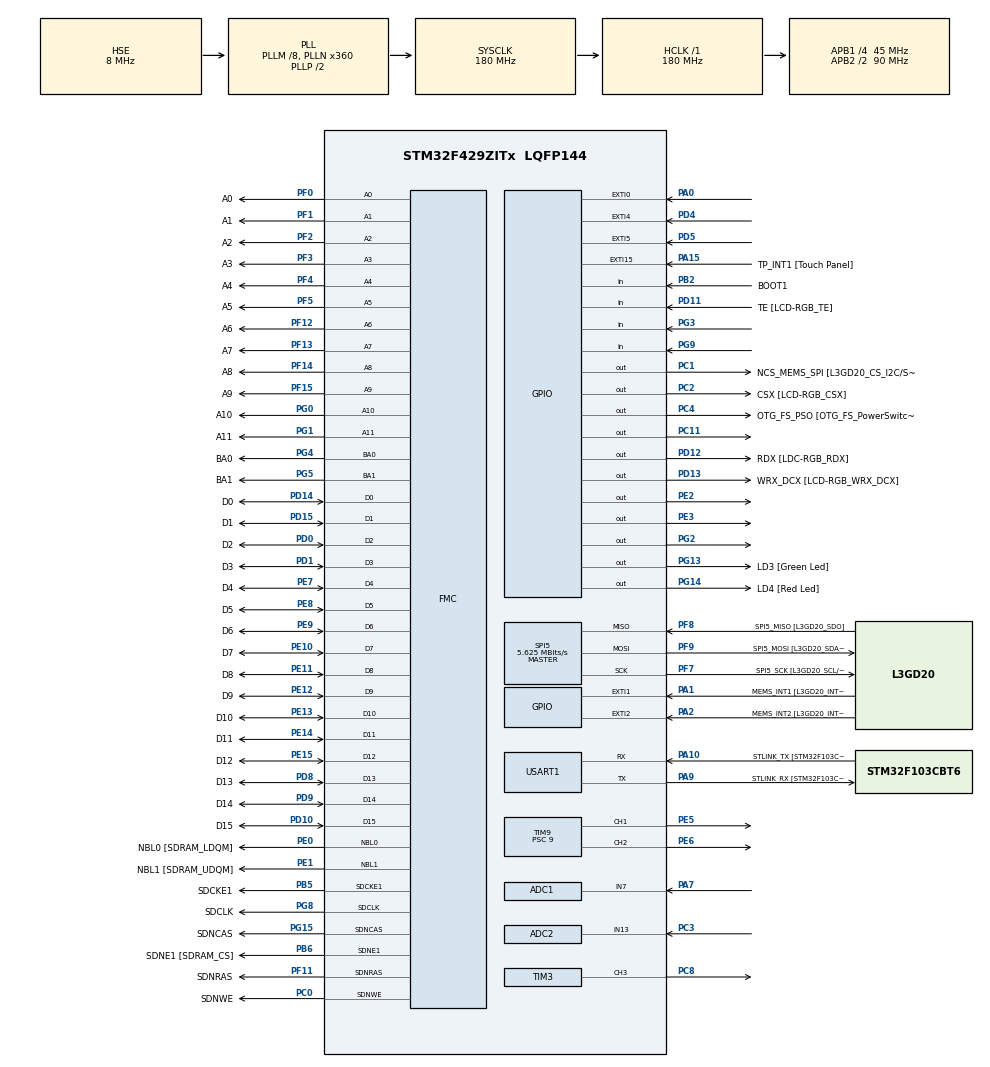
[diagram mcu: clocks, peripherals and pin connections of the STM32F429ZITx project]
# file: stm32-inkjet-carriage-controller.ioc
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ADC1.Channel-0\#ChannelRegularConversion=ADC_CHANNEL_7
ADC1.Mode=__NULL
ADC1.NbrOfConversionFlag=1
ADC1.Rank-0\#ChannelRegularConversion=1
ADC1.SamplingTime-0\#ChannelRegularConversion=ADC_SAMPLETIME_15CYCLES
ADC1.master=1
ADC2.Channel-0\#ChannelRegularConversion=ADC_CHANNEL_13
ADC2.NbrOfConversionFlag=1
ADC2.Rank-0\#ChannelRegularConversion=1
ADC2.SamplingTime-0\#ChannelRegularConversion=ADC_SAMPLETIME_15CYCLES
Dma.ADC1.0.Direction=DMA_PERIPH_TO_MEMORY
Dma.ADC1.0.FIFOMode=DMA_FIFOMODE_DISABLE
Dma.ADC1.0.Instance=DMA2_Stream0
Dma.ADC1.0.MemDataAlignment=DMA_MDATAALIGN_HALFWORD
Dma.ADC1.0.MemInc=DMA_MINC_ENABLE
Dma.ADC1.0.Mode=DMA_NORMAL
Dma.ADC1.0.PeriphDataAlignment=DMA_PDATAALIGN_HALFWORD
Dma.ADC1.0.PeriphInc=DMA_PINC_DISABLE
Dma.ADC1.0.Priority=DMA_PRIORITY_HIGH
Dma.ADC2.1.Direction=DMA_PERIPH_TO_MEMORY
Dma.ADC2.1.FIFOMode=DMA_FIFOMODE_DISABLE
Dma.ADC2.1.Instance=DMA2_Stream2
Dma.ADC2.1.MemDataAlignment=DMA_MDATAALIGN_HALFWORD
Dma.ADC2.1.MemInc=DMA_MINC_ENABLE
Dma.ADC2.1.Mode=DMA_NORMAL
Dma.ADC2.1.PeriphDataAlignment=DMA_PDATAALIGN_HALFWORD
Dma.ADC2.1.PeriphInc=DMA_PINC_DISABLE
Dma.ADC2.1.Priority=DMA_PRIORITY_HIGH
Dma.Request0=ADC1
Dma.Request1=ADC2
FMC.CASLatency1=FMC_SDRAM_CAS_LATENCY_3
FMC.ExitSelfRefreshDelay1=7
FMC.LoadToActiveDelay1=2
FMC.RCDDelay1=2
FMC.RPDelay1=2
FMC.RPDelay2=2
FMC.ReadBurst1=FMC_SDRAM_RBURST_DISABLE
FMC.ReadPipeDelay1=FMC_SDRAM_RPIPE_DELAY_1
FMC.ReadPipeDelay2=FMC_SDRAM_RPIPE_DELAY_1
FMC.RowCycleDelay1=7
FMC.RowCycleDelay2=7
FMC.SDClockPeriod1=FMC_SDRAM_CLOCK_PERIOD_2
FMC.SDClockPeriod2=FMC_SDRAM_CLOCK_PERIOD_2
FMC.SelfRefreshTime1=4
FMC.WriteRecoveryTime1=3
Mcu.Family=STM32F4
Mcu.Name=STM32F429ZITx
Mcu.Package=LQFP144
NVIC.DMA2_Stream0_IRQn=true\:2\:0\:true\:false\:true\:false\:true\:true
NVIC.DMA2_Stream2_IRQn=true\:2\:0\:true\:false\:true\:false\:true\:true
NVIC.PriorityGroup=NVIC_PRIORITYGROUP_4
PA0/WKUP.Signal=GPXTI0
PA1.GPIO_Label=MEMS_INT1 [L3GD20_INT1]
PA1.GPIO_ModeDefaultEXTI=GPIO_MODE_EVT_RISING
PA1.GPIO_PuPd=GPIO_NOPULL
PA1.Signal=GPXTI1
PA10.GPIO_Label=STLINK_TX [STM32F103CBT6_PA2]
PA10.Mode=Asynchronous
PA10.Signal=USART1_RX
PA11.GPIO_Label=R4
PA11.GPIO_Mode=GPIO_MODE_AF_PP
PA11.GPIO_PuPd=GPIO_NOPULL
PA11.GPIO_Speed=GPIO_SPEED_FREQ_LOW
PA11.Signal=LTDC_R4
PA12.GPIO_Label=R5
PA12.GPIO_Mode=GPIO_MODE_AF_PP
PA12.GPIO_PuPd=GPIO_NOPULL
PA12.GPIO_Speed=GPIO_SPEED_FREQ_LOW
PA12.Signal=LTDC_R5
PA13.GPIO_Label=SWDIO
PA13.Mode=Serial_Wire
PA13.Signal=SYS_JTMS-SWDIO
PA14.GPIO_Label=SWCLK
PA14.Mode=Serial_Wire
PA14.Signal=SYS_JTCK-SWCLK
PA15.GPIO_Label=TP_INT1 [Touch Panel]
PA15.GPIO_ModeDefaultEXTI=GPIO_MODE_EVT_RISING
PA15.GPIO_PuPd=GPIO_NOPULL
PA15.Signal=GPXTI15
PA2.GPIO_Label=MEMS_INT2 [L3GD20_INT2]
PA2.GPIO_ModeDefaultEXTI=GPIO_MODE_EVT_RISING
PA2.GPIO_PuPd=GPIO_NOPULL
PA2.Signal=GPXTI2
PA3.GPIO_Label=B5
PA3.GPIO_Mode=GPIO_MODE_AF_PP
PA3.GPIO_PuPd=GPIO_NOPULL
PA3.GPIO_Speed=GPIO_SPEED_FREQ_LOW
PA3.Signal=LTDC_B5
PA4.GPIO_Label=VSYNC
PA4.GPIO_Mode=GPIO_MODE_AF_PP
PA4.GPIO_PuPd=GPIO_NOPULL
PA4.GPIO_Speed=GPIO_SPEED_FREQ_LOW
PA4.Signal=LTDC_VSYNC
PA6.GPIO_Label=G2
PA6.GPIO_Mode=GPIO_MODE_AF_PP
PA6.GPIO_PuPd=GPIO_NOPULL
PA6.GPIO_Speed=GPIO_SPEED_FREQ_LOW
PA6.Signal=LTDC_G2
PA7.Signal=ADCx_IN7
PA8.GPIO_Label=I2C3_SCL [ACP/RF_SCL]
PA8.GPIO_Mode=GPIO_MODE_AF_OD
PA8.GPIO_Pu=GPIO_PULLUP
PA8.GPIO_PuPd=GPIO_NOPULL
PA8.GPIO_Speed=GPIO_SPEED_FREQ_LOW
PA8.Signal=I2C3_SCL
PA9.GPIO_Label=STLINK_RX [STM32F103CBT6_PA3]
PA9.Mode=Asynchronous
PA9.Signal=USART1_TX
PB0.GPIO_Label=R3
PB0.GPIO_Mode=GPIO_MODE_AF_PP
PB0.GPIO_PuPd=GPIO_NOPULL
PB0.GPIO_Speed=GPIO_SPEED_FREQ_LOW
PB0.Signal=LTDC_R3
PB1.GPIO_Label=R6
PB1.GPIO_Mode=GPIO_MODE_AF_PP
PB1.GPIO_PuPd=GPIO_NOPULL
PB1.GPIO_Speed=GPIO_SPEED_FREQ_LOW
PB1.Signal=LTDC_R6
PB10.GPIO_Label=G4
PB10.GPIO_Mode=GPIO_MODE_AF_PP
PB10.GPIO_PuPd=GPIO_NOPULL
PB10.GPIO_Speed=GPIO_SPEED_FREQ_LOW
PB10.Signal=LTDC_G4
PB11.GPIO_Label=G5
PB11.GPIO_Mode=GPIO_MODE_AF_PP
PB11.GPIO_PuPd=GPIO_NOPULL
PB11.GPIO_Speed=GPIO_SPEED_FREQ_LOW
PB11.Signal=LTDC_G5
PB12.GPIO_Label=OTG_HS_ID
PB12.GPIO_Mode=GPIO_MODE_AF_PP
PB12.GPIO_PuPd=GPIO_NOPULL
PB12.GPIO_Speed=GPIO_SPEED_FREQ_LOW
PB12.Signal=USB_OTG_HS_ID
PB13.GPIO_Label=VBUS_HS
PB13.GPIO_Mode=GPIO_MODE_INPUT
PB13.GPIO_PuPd=GPIO_NOPULL
PB13.Signal=USB_OTG_HS_VBUS
PB14.GPIO_Label=OTG_HS_DM
PB14.GPIO_Mode=GPIO_MODE_AF_PP
PB14.GPIO_PuPd=GPIO_NOPULL
PB14.GPIO_Speed=GPIO_SPEED_FREQ_LOW
PB14.Signal=USB_OTG_HS_DM
PB15.GPIO_Label=OTG_HS_DP
PB15.GPIO_Mode=GPIO_MODE_AF_PP
PB15.GPIO_PuPd=GPIO_NOPULL
PB15.GPIO_Speed=GPIO_SPEED_FREQ_LOW
PB15.Signal=USB_OTG_HS_DP
PB2/BOOT1.GPIO_Label=BOOT1
PB2/BOOT1.GPIO_Mode=GPIO_MODE_INPUT
PB2/BOOT1.GPIO_PuPd=GPIO_NOPULL
PB2/BOOT1.Signal=GPIO_Input
PB5.GPIO_Label=SDCKE1
PB5.GPIO_Mode=GPIO_MODE_AF_PP
PB5.GPIO_PuPd=GPIO_NOPULL
PB5.GPIO_Speed=GPIO_SPEED_FREQ_VERY_HIGH
PB5.Mode=SdramChipSelect2_1
PB5.Signal=FMC_SDCKE1
PB6.GPIO_Label=SDNE1 [SDRAM_CS]
PB6.GPIO_Mode=GPIO_MODE_AF_PP
PB6.GPIO_PuPd=GPIO_NOPULL
PB6.GPIO_Speed=GPIO_SPEED_FREQ_VERY_HIGH
PB6.Mode=SdramChipSelect2_1
PB6.Signal=FMC_SDNE1
PB8.GPIO_Label=B6
PB8.GPIO_Mode=GPIO_MODE_AF_PP
PB8.GPIO_PuPd=GPIO_NOPULL
PB8.GPIO_Speed=GPIO_SPEED_FREQ_LOW
PB8.Signal=LTDC_B6
PB9.GPIO_Label=B7
PB9.GPIO_Mode=GPIO_MODE_AF_PP
PB9.GPIO_PuPd=GPIO_NOPULL
PB9.GPIO_Speed=GPIO_SPEED_FREQ_LOW
PB9.Signal=LTDC_B7
PC0.GPIO_Label=SDNWE
PC0.GPIO_Mode=GPIO_MODE_AF_PP
PC0.GPIO_PuPd=GPIO_NOPULL
PC0.GPIO_Speed=GPIO_SPEED_FREQ_VERY_HIGH
PC0.Signal=FMC_SDNWE
PC1.GPIO_Label=NCS_MEMS_SPI [L3GD20_CS_I2C/SPI]
PC1.GPIO_Mode=GPIO_MODE_OUTPUT_PP
PC1.GPIO_PuPd=GPIO_NOPULL
PC1.GPIO_Speed=GPIO_SPEED_FREQ_LOW
PC1.Signal=GPIO_Output
PC10.GPIO_Label=R2
PC10.GPIO_Mode=GPIO_MODE_AF_PP
PC10.GPIO_PuPd=GPIO_NOPULL
PC10.GPIO_Speed=GPIO_SPEED_FREQ_LOW
PC10.Signal=LTDC_R2
PC11.Signal=GPIO_Output
PC14/OSC32_IN.GPIO_Label=PC14-OSC32_IN
PC14/OSC32_IN.Signal=RCC_OSC32_IN
PC15/OSC32_OUT.GPIO_Label=PC15-OSC32_OUT
PC15/OSC32_OUT.Signal=RCC_OSC32_OUT
PC2.GPIO_Label=CSX [LCD-RGB_CSX]
PC2.GPIO_Mode=GPIO_MODE_OUTPUT_PP
PC2.GPIO_PuPd=GPIO_NOPULL
PC2.GPIO_Speed=GPIO_SPEED_FREQ_LOW
PC2.Signal=GPIO_Output
PC3.Signal=ADCx_IN13
PC4.GPIO_Label=OTG_FS_PSO [OTG_FS_PowerSwitchOn]
PC4.GPIO_Mode=GPIO_MODE_OUTPUT_PP
PC4.GPIO_PuPd=GPIO_NOPULL
PC4.GPIO_Speed=GPIO_SPEED_FREQ_LOW
PC4.Signal=GPIO_Output
PC6.GPIO_Label=HSYNC
PC6.GPIO_Mode=GPIO_MODE_AF_PP
PC6.GPIO_PuPd=GPIO_NOPULL
PC6.GPIO_Speed=GPIO_SPEED_FREQ_LOW
PC6.Signal=LTDC_HSYNC
PC8.Signal=S_TIM3_CH3
PC9.GPIO_Label=I2C3_SDA [ACP/RF_SDA]
PC9.GPIO_Mode=GPIO_MODE_AF_OD
PC9.GPIO_Pu=GPIO_PULLUP
PC9.GPIO_PuPd=GPIO_NOPULL
PC9.GPIO_Speed=GPIO_SPEED_FREQ_LOW
PC9.Signal=I2C3_SDA
PD0.GPIO_Label=D2
PD0.GPIO_Mode=GPIO_MODE_AF_PP
PD0.GPIO_PuPd=GPIO_NOPULL
PD0.GPIO_Speed=GPIO_SPEED_FREQ_VERY_HIGH
PD0.Signal=FMC_D2_DA2
PD1.GPIO_Label=D3
PD1.GPIO_Mode=GPIO_MODE_AF_PP
PD1.GPIO_PuPd=GPIO_NOPULL
PD1.GPIO_Speed=GPIO_SPEED_FREQ_VERY_HIGH
PD1.Signal=FMC_D3_DA3
PD10.GPIO_Label=D15
PD10.GPIO_Mode=GPIO_MODE_AF_PP
PD10.GPIO_PuPd=GPIO_NOPULL
PD10.GPIO_Speed=GPIO_SPEED_FREQ_VERY_HIGH
PD10.Signal=FMC_D15_DA15
PD11.GPIO_Label=TE [LCD-RGB_TE]
PD11.GPIO_Mode=GPIO_MODE_INPUT
PD11.GPIO_PuPd=GPIO_NOPULL
PD11.Signal=GPIO_Input
PD12.GPIO_Label=RDX [LDC-RGB_RDX]
PD12.GPIO_Mode=GPIO_MODE_OUTPUT_PP
PD12.GPIO_PuPd=GPIO_NOPULL
PD12.GPIO_Speed=GPIO_SPEED_FREQ_LOW
PD12.Signal=GPIO_Output
PD13.GPIO_Label=WRX_DCX [LCD-RGB_WRX_DCX]
PD13.GPIO_Mode=GPIO_MODE_OUTPUT_PP
PD13.GPIO_PuPd=GPIO_NOPULL
PD13.GPIO_Speed=GPIO_SPEED_FREQ_LOW
PD13.Signal=GPIO_Output
PD14.GPIO_Label=D0
PD14.GPIO_Mode=GPIO_MODE_AF_PP
PD14.GPIO_PuPd=GPIO_NOPULL
PD14.GPIO_Speed=GPIO_SPEED_FREQ_VERY_HIGH
PD14.Signal=FMC_D0_DA0
PD15.GPIO_Label=D1
PD15.GPIO_Mode=GPIO_MODE_AF_PP
PD15.GPIO_PuPd=GPIO_NOPULL
PD15.GPIO_Speed=GPIO_SPEED_FREQ_VERY_HIGH
PD15.Signal=FMC_D1_DA1
PD3.GPIO_Label=G7
PD3.GPIO_Mode=GPIO_MODE_AF_PP
PD3.GPIO_PuPd=GPIO_NOPULL
PD3.GPIO_Speed=GPIO_SPEED_FREQ_LOW
PD3.Signal=LTDC_G7
PD4.Signal=GPXTI4
PD5.Signal=GPXTI5
PD6.GPIO_Label=B2
PD6.GPIO_Mode=GPIO_MODE_AF_PP
PD6.GPIO_PuPd=GPIO_NOPULL
PD6.GPIO_Speed=GPIO_SPEED_FREQ_LOW
PD6.Signal=LTDC_B2
PD8.GPIO_Label=D13
PD8.GPIO_Mode=GPIO_MODE_AF_PP
PD8.GPIO_PuPd=GPIO_NOPULL
PD8.GPIO_Speed=GPIO_SPEED_FREQ_VERY_HIGH
PD8.Signal=FMC_D13_DA13
PD9.GPIO_Label=D14
PD9.GPIO_Mode=GPIO_MODE_AF_PP
PD9.GPIO_PuPd=GPIO_NOPULL
PD9.GPIO_Speed=GPIO_SPEED_FREQ_VERY_HIGH
PD9.Signal=FMC_D14_DA14
PE0.GPIO_Label=NBL0 [SDRAM_LDQM]
PE0.GPIO_Mode=GPIO_MODE_AF_PP
PE0.GPIO_PuPd=GPIO_NOPULL
PE0.GPIO_Speed=GPIO_SPEED_FREQ_VERY_HIGH
PE0.Signal=FMC_NBL0
PE1.GPIO_Label=NBL1 [SDRAM_UDQM]
PE1.GPIO_Mode=GPIO_MODE_AF_PP
PE1.GPIO_PuPd=GPIO_NOPULL
PE1.GPIO_Speed=GPIO_SPEED_FREQ_VERY_HIGH
PE1.Signal=FMC_NBL1
PE10.GPIO_Label=D7
PE10.GPIO_Mode=GPIO_MODE_AF_PP
PE10.GPIO_PuPd=GPIO_NOPULL
PE10.GPIO_Speed=GPIO_SPEED_FREQ_VERY_HIGH
PE10.Signal=FMC_D7_DA7
PE11.GPIO_Label=D8
PE11.GPIO_Mode=GPIO_MODE_AF_PP
PE11.GPIO_PuPd=GPIO_NOPULL
PE11.GPIO_Speed=GPIO_SPEED_FREQ_VERY_HIGH
PE11.Signal=FMC_D8_DA8
PE12.GPIO_Label=D9
PE12.GPIO_Mode=GPIO_MODE_AF_PP
PE12.GPIO_PuPd=GPIO_NOPULL
PE12.GPIO_Speed=GPIO_SPEED_FREQ_VERY_HIGH
PE12.Signal=FMC_D9_DA9
PE13.GPIO_Label=D10
PE13.GPIO_Mode=GPIO_MODE_AF_PP
PE13.GPIO_PuPd=GPIO_NOPULL
PE13.GPIO_Speed=GPIO_SPEED_FREQ_VERY_HIGH
PE13.Signal=FMC_D10_DA10
PE14.GPIO_Label=D11
PE14.GPIO_Mode=GPIO_MODE_AF_PP
PE14.GPIO_PuPd=GPIO_NOPULL
PE14.GPIO_Speed=GPIO_SPEED_FREQ_VERY_HIGH
PE14.Signal=FMC_D11_DA11
PE15.GPIO_Label=D12
PE15.GPIO_Mode=GPIO_MODE_AF_PP
PE15.GPIO_PuPd=GPIO_NOPULL
PE15.GPIO_Speed=GPIO_SPEED_FREQ_VERY_HIGH
PE15.Signal=FMC_D12_DA12
PE2.Signal=GPIO_Output
PE3.Signal=GPIO_Output
PE5.Signal=S_TIM9_CH1
PE6.Signal=S_TIM9_CH2
PE7.GPIO_Label=D4
PE7.GPIO_Mode=GPIO_MODE_AF_PP
PE7.GPIO_PuPd=GPIO_NOPULL
PE7.GPIO_Speed=GPIO_SPEED_FREQ_VERY_HIGH
PE7.Signal=FMC_D4_DA4
PE8.GPIO_Label=D5
PE8.GPIO_Mode=GPIO_MODE_AF_PP
PE8.GPIO_PuPd=GPIO_NOPULL
PE8.GPIO_Speed=GPIO_SPEED_FREQ_VERY_HIGH
PE8.Signal=FMC_D5_DA5
PE9.GPIO_Label=D6
PE9.GPIO_Mode=GPIO_MODE_AF_PP
PE9.GPIO_PuPd=GPIO_NOPULL
PE9.GPIO_Speed=GPIO_SPEED_FREQ_VERY_HIGH
PE9.Signal=FMC_D6_DA6
PF0.GPIO_Label=A0
PF0.GPIO_Mode=GPIO_MODE_AF_PP
PF0.GPIO_PuPd=GPIO_NOPULL
PF0.GPIO_Speed=GPIO_SPEED_FREQ_VERY_HIGH
PF0.Signal=FMC_A0
PF1.GPIO_Label=A1
PF1.GPIO_Mode=GPIO_MODE_AF_PP
PF1.GPIO_PuPd=GPIO_NOPULL
PF1.GPIO_Speed=GPIO_SPEED_FREQ_VERY_HIGH
PF1.Signal=FMC_A1
PF10.GPIO_Label=ENABLE [LCD-RGB_ENABLE]
PF10.GPIO_Mode=GPIO_MODE_AF_PP
PF10.GPIO_PuPd=GPIO_NOPULL
PF10.GPIO_Speed=GPIO_SPEED_FREQ_LOW
PF10.Signal=LTDC_DE
PF11.GPIO_Label=SDNRAS
PF11.GPIO_Mode=GPIO_MODE_AF_PP
PF11.GPIO_PuPd=GPIO_NOPULL
PF11.GPIO_Speed=GPIO_SPEED_FREQ_VERY_HIGH
PF11.Signal=FMC_SDNRAS
PF12.GPIO_Label=A6
PF12.GPIO_Mode=GPIO_MODE_AF_PP
PF12.GPIO_PuPd=GPIO_NOPULL
PF12.GPIO_Speed=GPIO_SPEED_FREQ_VERY_HIGH
PF12.Signal=FMC_A6
PF13.GPIO_Label=A7
PF13.GPIO_Mode=GPIO_MODE_AF_PP
PF13.GPIO_PuPd=GPIO_NOPULL
PF13.GPIO_Speed=GPIO_SPEED_FREQ_VERY_HIGH
PF13.Signal=FMC_A7
PF14.GPIO_Label=A8
PF14.GPIO_Mode=GPIO_MODE_AF_PP
PF14.GPIO_PuPd=GPIO_NOPULL
PF14.GPIO_Speed=GPIO_SPEED_FREQ_VERY_HIGH
PF14.Signal=FMC_A8
PF15.GPIO_Label=A9
PF15.GPIO_Mode=GPIO_MODE_AF_PP
PF15.GPIO_PuPd=GPIO_NOPULL
PF15.GPIO_Speed=GPIO_SPEED_FREQ_VERY_HIGH
PF15.Signal=FMC_A9
PF2.GPIO_Label=A2
PF2.GPIO_Mode=GPIO_MODE_AF_PP
PF2.GPIO_PuPd=GPIO_NOPULL
PF2.GPIO_Speed=GPIO_SPEED_FREQ_VERY_HIGH
PF2.Signal=FMC_A2
PF3.GPIO_Label=A3
PF3.GPIO_Mode=GPIO_MODE_AF_PP
PF3.GPIO_PuPd=GPIO_NOPULL
PF3.GPIO_Speed=GPIO_SPEED_FREQ_VERY_HIGH
PF3.Signal=FMC_A3
PF4.GPIO_Label=A4
PF4.GPIO_Mode=GPIO_MODE_AF_PP
PF4.GPIO_PuPd=GPIO_NOPULL
PF4.GPIO_Speed=GPIO_SPEED_FREQ_VERY_HIGH
PF4.Signal=FMC_A4
PF5.GPIO_Label=A5
PF5.GPIO_Mode=GPIO_MODE_AF_PP
PF5.GPIO_PuPd=GPIO_NOPULL
PF5.GPIO_Speed=GPIO_SPEED_FREQ_VERY_HIGH
PF5.Signal=FMC_A5
PF7.GPIO_Label=SPI5_SCK [L3GD20_SCL/SPC]
PF7.GPIO_Mode=GPIO_MODE_AF_PP
PF7.GPIO_PuPd=GPIO_NOPULL
PF7.GPIO_Speed=GPIO_SPEED_FREQ_LOW
PF7.Mode=Full_Duplex_Master
PF7.Signal=SPI5_SCK
PF8.GPIO_Label=SPI5_MISO [L3GD20_SDO]
PF8.GPIO_Mode=GPIO_MODE_AF_PP
PF8.GPIO_PuPd=GPIO_NOPULL
PF8.GPIO_Speed=GPIO_SPEED_FREQ_LOW
PF8.Mode=Full_Duplex_Master
PF8.Signal=SPI5_MISO
PF9.GPIO_Label=SPI5_MOSI [L3GD20_SDA/SDI/SDO]
PF9.GPIO_Mode=GPIO_MODE_AF_PP
PF9.GPIO_PuPd=GPIO_NOPULL
PF9.GPIO_Speed=GPIO_SPEED_FREQ_LOW
PF9.Mode=Full_Duplex_Master
PF9.Signal=SPI5_MOSI
PG0.GPIO_Label=A10
PG0.GPIO_Mode=GPIO_MODE_AF_PP
PG0.GPIO_PuPd=GPIO_NOPULL
PG0.GPIO_Speed=GPIO_SPEED_FREQ_VERY_HIGH
PG0.Signal=FMC_A10
PG1.GPIO_Label=A11
PG1.GPIO_Mode=GPIO_MODE_AF_PP
PG1.GPIO_PuPd=GPIO_NOPULL
PG1.GPIO_Speed=GPIO_SPEED_FREQ_VERY_HIGH
PG1.Signal=FMC_A11
PG10.GPIO_Label=G3
PG10.GPIO_Mode=GPIO_MODE_AF_PP
PG10.GPIO_PuPd=GPIO_NOPULL
PG10.GPIO_Speed=GPIO_SPEED_FREQ_LOW
PG10.Signal=LTDC_G3
PG11.GPIO_Label=B3
PG11.GPIO_Mode=GPIO_MODE_AF_PP
PG11.GPIO_PuPd=GPIO_NOPULL
PG11.GPIO_Speed=GPIO_SPEED_FREQ_LOW
PG11.Signal=LTDC_B3
PG12.GPIO_Label=B4
PG12.GPIO_Mode=GPIO_MODE_AF_PP
PG12.GPIO_PuPd=GPIO_NOPULL
PG12.GPIO_Speed=GPIO_SPEED_FREQ_LOW
PG12.Signal=LTDC_B4
PG13.GPIO_Label=LD3 [Green Led]
PG13.GPIO_Mode=GPIO_MODE_OUTPUT_PP
PG13.GPIO_PuPd=GPIO_NOPULL
PG13.GPIO_Speed=GPIO_SPEED_FREQ_LOW
PG13.Signal=GPIO_Output
PG14.GPIO_Label=LD4 [Red Led]
PG14.GPIO_Mode=GPIO_MODE_OUTPUT_PP
PG14.GPIO_PuPd=GPIO_NOPULL
PG14.GPIO_Speed=GPIO_SPEED_FREQ_LOW
PG14.Signal=GPIO_Output
PG15.GPIO_Label=SDNCAS
PG15.GPIO_Mode=GPIO_MODE_AF_PP
PG15.GPIO_PuPd=GPIO_NOPULL
PG15.GPIO_Speed=GPIO_SPEED_FREQ_VERY_HIGH
PG15.Signal=FMC_SDNCAS
PG2.Signal=GPIO_Output
PG3.Signal=GPIO_Input
PG4.GPIO_Label=BA0
PG4.GPIO_Mode=GPIO_MODE_AF_PP
PG4.GPIO_PuPd=GPIO_NOPULL
PG4.GPIO_Speed=GPIO_SPEED_FREQ_VERY_HIGH
PG4.Signal=FMC_A14_BA0
PG5.GPIO_Label=BA1
PG5.GPIO_Mode=GPIO_MODE_AF_PP
PG5.GPIO_PuPd=GPIO_NOPULL
PG5.GPIO_Speed=GPIO_SPEED_FREQ_VERY_HIGH
PG5.Signal=FMC_A15_BA1
PG6.GPIO_Label=R7
PG6.GPIO_Mode=GPIO_MODE_AF_PP
PG6.GPIO_PuPd=GPIO_NOPULL
PG6.GPIO_Speed=GPIO_SPEED_FREQ_LOW
PG6.Signal=LTDC_R7
PG7.GPIO_Label=DOTCLK [LCT-RGB_DOTCLK]
PG7.GPIO_Mode=GPIO_MODE_AF_PP
PG7.GPIO_PuPd=GPIO_NOPULL
PG7.GPIO_Speed=GPIO_SPEED_FREQ_LOW
PG7.Signal=LTDC_CLK
PG8.GPIO_Label=SDCLK
PG8.GPIO_Mode=GPIO_MODE_AF_PP
PG8.GPIO_PuPd=GPIO_NOPULL
PG8.GPIO_Speed=GPIO_SPEED_FREQ_VERY_HIGH
PG8.Signal=FMC_SDCLK
PG9.Signal=GPIO_Input
PH0/OSC_IN.GPIO_Label=PH0-OSC_IN
PH0/OSC_IN.Mode=HSE-External-Oscillator
PH0/OSC_IN.Signal=RCC_OSC_IN
PH1/OSC_OUT.GPIO_Label=PH1-OSC_OUT
PH1/OSC_OUT.Mode=HSE-External-Oscillator
PH1/OSC_OUT.Signal=RCC_OSC_OUT
ProjectManager.HeapSize=0x200
ProjectManager.StackSize=0x400
ProjectManager.TargetToolchain=STM32CubeIDE
RCC.48MHZClocksFreq_Value=51428571.428571425
RCC.AHBFreq_Value=180000000
RCC.APB1CLKDivider=RCC_HCLK_DIV4
RCC.APB1Freq_Value=45000000
RCC.APB1TimFreq_Value=90000000
RCC.APB2CLKDivider=RCC_HCLK_DIV2
RCC.APB2Freq_Value=90000000
RCC.APB2TimFreq_Value=180000000
RCC.CortexFreq_Value=180000000
RCC.HCLKFreq_Value=180000000
RCC.HSE_VALUE=8000000
RCC.HSI_VALUE=16000000
RCC.LSE_VALUE=32768
RCC.PLLM=8
RCC.PLLN=360
RCC.PLLQ=7
RCC.PLLSAIN=120
RCC.PLLSourceVirtual=RCC_PLLSOURCE_HSE
RCC.SYSCLKFreq_VALUE=180000000
RCC.SYSCLKSource=RCC_SYSCLKSOURCE_PLLCLK
RCC.VCOOutputFreq_Value=360000000
SH.ADCx_IN13.0=ADC2_IN13,IN13
SH.ADCx_IN7.0=ADC1_IN7,IN7
SH.FMC_A0.0=FMC_A0,12b-sda1
SH.FMC_A1.0=FMC_A1,12b-sda1
SH.FMC_A10.0=FMC_A10,12b-sda1
SH.FMC_A11.0=FMC_A11,12b-sda1
SH.FMC_A14_BA0.0=FMC_BA0,FourSdramBanks1
SH.FMC_A15_BA1.0=FMC_BA1,FourSdramBanks1
SH.FMC_A2.0=FMC_A2,12b-sda1
SH.FMC_A3.0=FMC_A3,12b-sda1
SH.FMC_A4.0=FMC_A4,12b-sda1
SH.FMC_A5.0=FMC_A5,12b-sda1
SH.FMC_A6.0=FMC_A6,12b-sda1
SH.FMC_A7.0=FMC_A7,12b-sda1
SH.FMC_A8.0=FMC_A8,12b-sda1
SH.FMC_A9.0=FMC_A9,12b-sda1
SH.FMC_D0_DA0.0=FMC_D0,sd-16b-d1
SH.FMC_D10_DA10.0=FMC_D10,sd-16b-d1
SH.FMC_D11_DA11.0=FMC_D11,sd-16b-d1
SH.FMC_D12_DA12.0=FMC_D12,sd-16b-d1
SH.FMC_D13_DA13.0=FMC_D13,sd-16b-d1
SH.FMC_D14_DA14.0=FMC_D14,sd-16b-d1
SH.FMC_D15_DA15.0=FMC_D15,sd-16b-d1
SH.FMC_D1_DA1.0=FMC_D1,sd-16b-d1
SH.FMC_D2_DA2.0=FMC_D2,sd-16b-d1
SH.FMC_D3_DA3.0=FMC_D3,sd-16b-d1
SH.FMC_D4_DA4.0=FMC_D4,sd-16b-d1
SH.FMC_D5_DA5.0=FMC_D5,sd-16b-d1
SH.FMC_D6_DA6.0=FMC_D6,sd-16b-d1
SH.FMC_D7_DA7.0=FMC_D7,sd-16b-d1
SH.FMC_D8_DA8.0=FMC_D8,sd-16b-d1
SH.FMC_D9_DA9.0=FMC_D9,sd-16b-d1
SH.FMC_NBL0.0=FMC_NBL0,Sd2ByteEnable1
SH.FMC_NBL1.0=FMC_NBL1,Sd2ByteEnable1
SH.FMC_SDCLK.0=FMC_SDCLK,12b-sda1
SH.FMC_SDNCAS.0=FMC_SDNCAS,12b-sda1
SH.FMC_SDNRAS.0=FMC_SDNRAS,12b-sda1
SH.FMC_SDNWE.0=FMC_SDNWE,12b-sda1
SH.S_TIM3_CH3.0=TIM3_CH3,PWM Generation3 CH3
SH.S_TIM9_CH1.0=TIM9_CH1,Output Compare1 CH1
SH.S_TIM9_CH2.0=TIM9_CH2,Output Compare2 CH2
SPI5.BaudRatePrescaler=SPI_BAUDRATEPRESCALER_16
SPI5.CalculateBaudRate=5.625 MBits/s
SPI5.Direction=SPI_DIRECTION_2LINES
SPI5.Mode=SPI_MODE_MASTER
SPI5.VirtualType=VM_MASTER
TIM2.Prescaler=89
TIM3.Channel-PWM\ Generation3\ CH3=TIM_CHANNEL_3
TIM3.OCMode_PWM-PWM\ Generation3\ CH3=TIM_OCMODE_PWM2
TIM3.Period=50
TIM3.Prescaler=89
TIM3.Pulse-PWM\ Generation3\ CH3=1
TIM9.AutoReloadPreload=TIM_AUTORELOAD_PRELOAD_ENABLE
TIM9.Channel-Output\ Compare1\ CH1=TIM_CHANNEL_1
TIM9.Channel-Output\ Compare2\ CH2=TIM_CHANNEL_2
TIM9.OCMode_1=TIM_OCMODE_TOGGLE
TIM9.OCMode_2=TIM_OCMODE_TOGGLE
TIM9.Period=8999
TIM9.Prescaler=9
TIM9.Pulse-Output\ Compare2\ CH2=2250
USART1.VirtualMode=VM_ASYNC
VP_TIM1_VS_ClockSourceINT.Mode=Internal
VP_TIM2_VS_ClockSourceINT.Mode=Internal
VP_TIM3_VS_ClockSourceINT.Mode=Internal
VP_TIM3_VS_OPM.Mode=OPM_bit
VP_TIM9_VS_ClockSourceINT.Mode=Internal
board=STM32F429I-DISC1

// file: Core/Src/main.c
/* USER CODE BEGIN Header */
/**
  ******************************************************************************
  * @file           : main.c
  * @brief          : Main program body
  ******************************************************************************
  * @attention
  *
  * Copyright (c) 2026 STMicroelectronics.
  * All rights reserved.
  *
  * This software is licensed under terms that can be found in the LICENSE file
  * in the root directory of this software component.
  * If no LICENSE file comes with this software, it is provided AS-IS.
  *
  ******************************************************************************
  */
/* USER CODE END Header */
#include "main.h"

/* USER CODE BEGIN Includes */
#include "display.h"
/* USER CODE END Includes */

ADC_HandleTypeDef hadc1;
ADC_HandleTypeDef hadc2;
DMA_HandleTypeDef hdma_adc1;
DMA_HandleTypeDef hdma_adc2;

SPI_HandleTypeDef hspi5;

TIM_HandleTypeDef htim1;
TIM_HandleTypeDef htim2;
TIM_HandleTypeDef htim3;
TIM_HandleTypeDef htim9;

UART_HandleTypeDef huart1;

SDRAM_HandleTypeDef hsdram1;

/* USER CODE BEGIN PV */
volatile print_state_t state = IDLE;
volatile uint32_t edge_count = 0;
volatile uint32_t t_start = 0;
volatile uint32_t t_end = 0;
volatile uint32_t dt_ticks = 0;
volatile dir_t current_dir = DIR_UNKNOWN;
volatile float v_avg_mps = 0.0f;
volatile float v_avg_cms = 0.0f;
uint16_t arr = 0;
volatile uint32_t last_edge_time = 0;
volatile uint32_t expected_dt = 0;
volatile uint8_t edge_sample_state = 0;  // 0=no edge yet, 1=one edge recorded, 2=baseline captured
uint16_t FrontSensor_ORG[3000] __attribute__((section(".front_sensor")));
uint16_t RearSensor_ORG[3000]  __attribute__((section(".rear_sensor")));
volatile uint32_t edge_idx_after_idx = 0;
volatile uint8_t adc_armed = 0;
volatile uint8_t adc_capture_done = 0;
float FrontSensorProc_ORG[300] __attribute__((section(".front_proc")));
float RearSensorProc_ORG[300]  __attribute__((section(".rear_proc")));
volatile uint16_t front_min_raw = 0;
volatile uint16_t front_max_raw = 0;
volatile uint16_t rear_min_raw = 0;
volatile uint16_t rear_max_raw = 0;
volatile float front_min_mm = 0.0f;
volatile float front_max_mm = 0.0f;
volatile float front_avg_mm = 0.0f;
volatile float rear_min_mm = 0.0f;
volatile float rear_max_mm = 0.0f;
volatile float rear_avg_mm = 0.0f;
volatile uint32_t adc_swstart_count = 0; /* DEBUG: validation counter, remove for final submission */
/* USER CODE END PV */

void SystemClock_Config(void);
static void MX_GPIO_Init(void);
static void MX_DMA_Init(void);
static void MX_FMC_Init(void);
static void MX_SPI5_Init(void);
static void MX_TIM1_Init(void);
static void MX_TIM9_Init(void);
static void MX_USART1_UART_Init(void);
static void MX_TIM3_Init(void);
static void MX_TIM2_Init(void);
static void MX_ADC1_Init(void);
static void MX_ADC2_Init(void);
/* USER CODE BEGIN PFP */
void EXTI_Init(void);
static void Sensors_Arm(void);
uint16_t findMin(uint16_t *buf);
uint16_t findMax(uint16_t *buf);
static float rawToMm(uint16_t raw);
static void buildProcessedTable(uint16_t *src, float *dst);
static void computeStats(uint16_t *buf, volatile float *out_min, volatile float *out_max, volatile float *out_avg);
/* USER CODE END PFP */

int main(void)
{

  /* MCU Configuration--------------------------------------------------------*/

  /* Reset of all peripherals, Initializes the Flash interface and the Systick. */
  HAL_Init();

  /* Configure the system clock */
  SystemClock_Config();

  /* Initialize all configured peripherals */
  MX_GPIO_Init();
  MX_DMA_Init();
  MX_FMC_Init();
  MX_SPI5_Init();
  MX_TIM1_Init();
  MX_TIM9_Init();
  MX_USART1_UART_Init();
  MX_TIM3_Init();
  MX_TIM2_Init();
  MX_ADC1_Init();
  MX_ADC2_Init();
  /* USER CODE BEGIN 2 */

  DisplayInit();
  EXTI_Init();
  Sensors_Arm();

  const uint16_t speed_arr[4] = {17999, 13845, 11249, 8999};

  uint8_t sel0 = HAL_GPIO_ReadPin(GPIOG, GPIO_PIN_3);
  uint8_t sel1 = HAL_GPIO_ReadPin(GPIOG, GPIO_PIN_9);
  uint8_t speed_idx = (sel1 << 1) | sel0;

  arr = speed_arr[speed_idx];
  __HAL_TIM_SET_AUTORELOAD(&htim9, arr);
  __HAL_TIM_SET_COMPARE(&htim9, TIM_CHANNEL_2, (arr + 1) / 2);

  HAL_TIM_OC_Start(&htim9, TIM_CHANNEL_1);
  HAL_TIM_OC_Start(&htim9, TIM_CHANNEL_2);

  __HAL_TIM_SET_COUNTER(&htim3, 0);
  __HAL_TIM_CLEAR_FLAG(&htim3, TIM_FLAG_UPDATE | TIM_FLAG_CC1);
  HAL_TIM_PWM_Start(&htim3, TIM_CHANNEL_3);

  HAL_TIM_Base_Start(&htim2);
  /* USER CODE END 2 */

  /* Infinite loop */
  while (1)
  {

    /* USER CODE BEGIN 3 */

    if (state == DONE_OK)
    {
      dt_ticks = t_end - t_start;

      if (dt_ticks > 0) {
          v_avg_mps = 600000.0f / (float)dt_ticks;
          v_avg_cms = v_avg_mps * 100.0f;
      }
      GPIOE->BSRR = GPIO_PIN_2;   // EOP on
      GPIOG->BSRR = GPIO_PIN_13;  // LED3 green on

      current_dir = DIR_UNKNOWN;

      __HAL_TIM_SET_AUTORELOAD(&htim9, arr);
      __HAL_TIM_SET_COMPARE(&htim9, TIM_CHANNEL_1, (arr + 1) / 2);
      __HAL_TIM_SET_COMPARE(&htim9, TIM_CHANNEL_2, 0);

      edge_count = 0;
      state = RETURN_TRIP;

      if (adc_capture_done == 0x3) {
        adc_capture_done = 0;
        adc_armed = 0;

        buildProcessedTable(FrontSensor_ORG, FrontSensorProc_ORG);
        buildProcessedTable(RearSensor_ORG,  RearSensorProc_ORG);

        computeStats(FrontSensor_ORG, &front_min_mm, &front_max_mm, &front_avg_mm);
        computeStats(RearSensor_ORG,  &rear_min_mm,  &rear_max_mm,  &rear_avg_mm);

        front_min_raw = findMin(FrontSensor_ORG);
        front_max_raw = findMax(FrontSensor_ORG);
        rear_min_raw = findMin(RearSensor_ORG);
        rear_max_raw = findMax(RearSensor_ORG);

        DisplayUpdate();
      }

      GPIOE->BSRR = (GPIO_PIN_2 << 16);   // EOP off
      GPIOG->BSRR = (GPIO_PIN_13 << 16);   // green LED off

      Sensors_Arm();

    }
    else if (state == DONE_ERR)
    {
      GPIOC->BSRR = GPIO_PIN_11;      // OUTERR on
      GPIOG->BSRR = GPIO_PIN_14;      // LED4 red on

      HAL_Delay(10);

      GPIOC->BSRR = (GPIO_PIN_11 << 16);   // OUTERR off
      GPIOG->BSRR = (GPIO_PIN_14 << 16);   //red LED off

      current_dir = DIR_UNKNOWN;
      edge_sample_state = 0;
      Sensors_Arm();
      state = IDLE;
    }
  }
  /* USER CODE END 3 */
}

void SystemClock_Config(void)
{
  RCC_OscInitTypeDef RCC_OscInitStruct = {0};
  RCC_ClkInitTypeDef RCC_ClkInitStruct = {0};

  /** Configure the main internal regulator output voltage
  */
  __HAL_RCC_PWR_CLK_ENABLE();
  __HAL_PWR_VOLTAGESCALING_CONFIG(PWR_REGULATOR_VOLTAGE_SCALE1);

  /** Initializes the RCC Oscillators according to the specified parameters
  * in the RCC_OscInitTypeDef structure.
  */
  RCC_OscInitStruct.OscillatorType = RCC_OSCILLATORTYPE_HSE;
  RCC_OscInitStruct.HSEState = RCC_HSE_ON;
  RCC_OscInitStruct.PLL.PLLState = RCC_PLL_ON;
  RCC_OscInitStruct.PLL.PLLSource = RCC_PLLSOURCE_HSE;
  RCC_OscInitStruct.PLL.PLLM = 8;
  RCC_OscInitStruct.PLL.PLLN = 360;
  RCC_OscInitStruct.PLL.PLLP = RCC_PLLP_DIV2;
  RCC_OscInitStruct.PLL.PLLQ = 7;
  if (HAL_RCC_OscConfig(&RCC_OscInitStruct) != HAL_OK)
  {
    Error_Handler();
  }

  /** Activate the Over-Drive mode
  */
  if (HAL_PWREx_EnableOverDrive() != HAL_OK)
  {
    Error_Handler();
  }

  /** Initializes the CPU, AHB and APB buses clocks
  */
  RCC_ClkInitStruct.ClockType = RCC_CLOCKTYPE_HCLK|RCC_CLOCKTYPE_SYSCLK
                              |RCC_CLOCKTYPE_PCLK1|RCC_CLOCKTYPE_PCLK2;
  RCC_ClkInitStruct.SYSCLKSource = RCC_SYSCLKSOURCE_PLLCLK;
  RCC_ClkInitStruct.AHBCLKDivider = RCC_SYSCLK_DIV1;
  RCC_ClkInitStruct.APB1CLKDivider = RCC_HCLK_DIV4;
  RCC_ClkInitStruct.APB2CLKDivider = RCC_HCLK_DIV2;

  if (HAL_RCC_ClockConfig(&RCC_ClkInitStruct, FLASH_LATENCY_5) != HAL_OK)
  {
    Error_Handler();
  }
}

static void MX_ADC1_Init(void)
{

  ADC_ChannelConfTypeDef sConfig = {0};

  /** Configure the global features of the ADC (Clock, Resolution, Data Alignment and number of conversion)
  */
  hadc1.Instance = ADC1;
  hadc1.Init.ClockPrescaler = ADC_CLOCK_SYNC_PCLK_DIV4;
  hadc1.Init.Resolution = ADC_RESOLUTION_12B;
  hadc1.Init.ScanConvMode = DISABLE;
  hadc1.Init.ContinuousConvMode = DISABLE;
  hadc1.Init.DiscontinuousConvMode = DISABLE;
  hadc1.Init.ExternalTrigConvEdge = ADC_EXTERNALTRIGCONVEDGE_NONE;
  hadc1.Init.ExternalTrigConv = ADC_SOFTWARE_START;
  hadc1.Init.DataAlign = ADC_DATAALIGN_RIGHT;
  hadc1.Init.NbrOfConversion = 1;
  hadc1.Init.DMAContinuousRequests = DISABLE;
  hadc1.Init.EOCSelection = ADC_EOC_SINGLE_CONV;
  if (HAL_ADC_Init(&hadc1) != HAL_OK)
  {
    Error_Handler();
  }

  /** Configure for the selected ADC regular channel its corresponding rank in the sequencer and its sample time.
  */
  sConfig.Channel = ADC_CHANNEL_7;
  sConfig.Rank = 1;
  sConfig.SamplingTime = ADC_SAMPLETIME_15CYCLES;
  if (HAL_ADC_ConfigChannel(&hadc1, &sConfig) != HAL_OK)
  {
    Error_Handler();
  }

}

static void MX_ADC2_Init(void)
{

  ADC_ChannelConfTypeDef sConfig = {0};

  /** Configure the global features of the ADC (Clock, Resolution, Data Alignment and number of conversion)
  */
  hadc2.Instance = ADC2;
  hadc2.Init.ClockPrescaler = ADC_CLOCK_SYNC_PCLK_DIV4;
  hadc2.Init.Resolution = ADC_RESOLUTION_12B;
  hadc2.Init.ScanConvMode = DISABLE;
  hadc2.Init.ContinuousConvMode = DISABLE;
  hadc2.Init.DiscontinuousConvMode = DISABLE;
  hadc2.Init.ExternalTrigConvEdge = ADC_EXTERNALTRIGCONVEDGE_NONE;
  hadc2.Init.ExternalTrigConv = ADC_SOFTWARE_START;
  hadc2.Init.DataAlign = ADC_DATAALIGN_RIGHT;
  hadc2.Init.NbrOfConversion = 1;
  hadc2.Init.DMAContinuousRequests = DISABLE;
  hadc2.Init.EOCSelection = ADC_EOC_SINGLE_CONV;
  if (HAL_ADC_Init(&hadc2) != HAL_OK)
  {
    Error_Handler();
  }

  /** Configure for the selected ADC regular channel its corresponding rank in the sequencer and its sample time.
  */
  sConfig.Channel = ADC_CHANNEL_13;
  sConfig.Rank = 1;
  sConfig.SamplingTime = ADC_SAMPLETIME_15CYCLES;
  if (HAL_ADC_ConfigChannel(&hadc2, &sConfig) != HAL_OK)
  {
    Error_Handler();
  }

}

static void MX_SPI5_Init(void)
{

  /* SPI5 parameter configuration*/
  hspi5.Instance = SPI5;
  hspi5.Init.Mode = SPI_MODE_MASTER;
  hspi5.Init.Direction = SPI_DIRECTION_2LINES;
  hspi5.Init.DataSize = SPI_DATASIZE_8BIT;
  hspi5.Init.CLKPolarity = SPI_POLARITY_LOW;
  hspi5.Init.CLKPhase = SPI_PHASE_1EDGE;
  hspi5.Init.NSS = SPI_NSS_SOFT;
  hspi5.Init.BaudRatePrescaler = SPI_BAUDRATEPRESCALER_16;
  hspi5.Init.FirstBit = SPI_FIRSTBIT_MSB;
  hspi5.Init.TIMode = SPI_TIMODE_DISABLE;
  hspi5.Init.CRCCalculation = SPI_CRCCALCULATION_DISABLE;
  hspi5.Init.CRCPolynomial = 10;
  if (HAL_SPI_Init(&hspi5) != HAL_OK)
  {
    Error_Handler();
  }

}

static void MX_TIM1_Init(void)
{

  TIM_ClockConfigTypeDef sClockSourceConfig = {0};
  TIM_MasterConfigTypeDef sMasterConfig = {0};

  htim1.Instance = TIM1;
  htim1.Init.Prescaler = 0;
  htim1.Init.CounterMode = TIM_COUNTERMODE_UP;
  htim1.Init.Period = 65535;
  htim1.Init.ClockDivision = TIM_CLOCKDIVISION_DIV1;
  htim1.Init.RepetitionCounter = 0;
  htim1.Init.AutoReloadPreload = TIM_AUTORELOAD_PRELOAD_DISABLE;
  if (HAL_TIM_Base_Init(&htim1) != HAL_OK)
  {
    Error_Handler();
  }
  sClockSourceConfig.ClockSource = TIM_CLOCKSOURCE_INTERNAL;
  if (HAL_TIM_ConfigClockSource(&htim1, &sClockSourceConfig) != HAL_OK)
  {
    Error_Handler();
  }
  sMasterConfig.MasterOutputTrigger = TIM_TRGO_RESET;
  sMasterConfig.MasterSlaveMode = TIM_MASTERSLAVEMODE_DISABLE;
  if (HAL_TIMEx_MasterConfigSynchronization(&htim1, &sMasterConfig) != HAL_OK)
  {
    Error_Handler();
  }

}

static void MX_TIM2_Init(void)
{

  TIM_ClockConfigTypeDef sClockSourceConfig = {0};
  TIM_MasterConfigTypeDef sMasterConfig = {0};

  htim2.Instance = TIM2;
  htim2.Init.Prescaler = 89;
  htim2.Init.CounterMode = TIM_COUNTERMODE_UP;
  htim2.Init.Period = 4294967295;
  htim2.Init.ClockDivision = TIM_CLOCKDIVISION_DIV1;
  htim2.Init.AutoReloadPreload = TIM_AUTORELOAD_PRELOAD_DISABLE;
  if (HAL_TIM_Base_Init(&htim2) != HAL_OK)
  {
    Error_Handler();
  }
  sClockSourceConfig.ClockSource = TIM_CLOCKSOURCE_INTERNAL;
  if (HAL_TIM_ConfigClockSource(&htim2, &sClockSourceConfig) != HAL_OK)
  {
    Error_Handler();
  }
  sMasterConfig.MasterOutputTrigger = TIM_TRGO_RESET;
  sMasterConfig.MasterSlaveMode = TIM_MASTERSLAVEMODE_DISABLE;
  if (HAL_TIMEx_MasterConfigSynchronization(&htim2, &sMasterConfig) != HAL_OK)
  {
    Error_Handler();
  }

}

static void MX_TIM3_Init(void)
{

  TIM_ClockConfigTypeDef sClockSourceConfig = {0};
  TIM_MasterConfigTypeDef sMasterConfig = {0};
  TIM_OC_InitTypeDef sConfigOC = {0};

  htim3.Instance = TIM3;
  htim3.Init.Prescaler = 89;
  htim3.Init.CounterMode = TIM_COUNTERMODE_UP;
  htim3.Init.Period = 50;
  htim3.Init.ClockDivision = TIM_CLOCKDIVISION_DIV1;
  htim3.Init.AutoReloadPreload = TIM_AUTORELOAD_PRELOAD_DISABLE;
  if (HAL_TIM_Base_Init(&htim3) != HAL_OK)
  {
    Error_Handler();
  }
  sClockSourceConfig.ClockSource = TIM_CLOCKSOURCE_INTERNAL;
  if (HAL_TIM_ConfigClockSource(&htim3, &sClockSourceConfig) != HAL_OK)
  {
    Error_Handler();
  }
  if (HAL_TIM_PWM_Init(&htim3) != HAL_OK)
  {
    Error_Handler();
  }
  if (HAL_TIM_OnePulse_Init(&htim3, TIM_OPMODE_SINGLE) != HAL_OK)
  {
    Error_Handler();
  }
  sMasterConfig.MasterOutputTrigger = TIM_TRGO_RESET;
  sMasterConfig.MasterSlaveMode = TIM_MASTERSLAVEMODE_DISABLE;
  if (HAL_TIMEx_MasterConfigSynchronization(&htim3, &sMasterConfig) != HAL_OK)
  {
    Error_Handler();
  }
  sConfigOC.OCMode = TIM_OCMODE_PWM2;
  sConfigOC.Pulse = 1;
  sConfigOC.OCPolarity = TIM_OCPOLARITY_HIGH;
  sConfigOC.OCFastMode = TIM_OCFAST_DISABLE;
  if (HAL_TIM_PWM_ConfigChannel(&htim3, &sConfigOC, TIM_CHANNEL_3) != HAL_OK)
  {
    Error_Handler();
  }
  HAL_TIM_MspPostInit(&htim3);

}

static void MX_TIM9_Init(void)
{

  TIM_ClockConfigTypeDef sClockSourceConfig = {0};
  TIM_OC_InitTypeDef sConfigOC = {0};

  htim9.Instance = TIM9;
  htim9.Init.Prescaler = 9;
  htim9.Init.CounterMode = TIM_COUNTERMODE_UP;
  htim9.Init.Period = 8999;
  htim9.Init.ClockDivision = TIM_CLOCKDIVISION_DIV1;
  htim9.Init.AutoReloadPreload = TIM_AUTORELOAD_PRELOAD_ENABLE;
  if (HAL_TIM_Base_Init(&htim9) != HAL_OK)
  {
    Error_Handler();
  }
  sClockSourceConfig.ClockSource = TIM_CLOCKSOURCE_INTERNAL;
  if (HAL_TIM_ConfigClockSource(&htim9, &sClockSourceConfig) != HAL_OK)
  {
    Error_Handler();
  }
  if (HAL_TIM_OC_Init(&htim9) != HAL_OK)
  {
    Error_Handler();
  }
  sConfigOC.OCMode = TIM_OCMODE_TOGGLE;
  sConfigOC.Pulse = 0;
  sConfigOC.OCPolarity = TIM_OCPOLARITY_HIGH;
  sConfigOC.OCFastMode = TIM_OCFAST_DISABLE;
  if (HAL_TIM_OC_ConfigChannel(&htim9, &sConfigOC, TIM_CHANNEL_1) != HAL_OK)
  {
    Error_Handler();
  }
  sConfigOC.Pulse = 2250;
  if (HAL_TIM_OC_ConfigChannel(&htim9, &sConfigOC, TIM_CHANNEL_2) != HAL_OK)
  {
    Error_Handler();
  }
  HAL_TIM_MspPostInit(&htim9);

}

static void MX_USART1_UART_Init(void)
{

  huart1.Instance = USART1;
  huart1.Init.BaudRate = 115200;
  huart1.Init.WordLength = UART_WORDLENGTH_8B;
  huart1.Init.StopBits = UART_STOPBITS_1;
  huart1.Init.Parity = UART_PARITY_NONE;
  huart1.Init.Mode = UART_MODE_TX_RX;
  huart1.Init.HwFlowCtl = UART_HWCONTROL_NONE;
  huart1.Init.OverSampling = UART_OVERSAMPLING_16;
  if (HAL_UART_Init(&huart1) != HAL_OK)
  {
    Error_Handler();
  }

}

static void MX_DMA_Init(void)
{

  /* DMA controller clock enable */
  __HAL_RCC_DMA2_CLK_ENABLE();

  /* DMA interrupt init */
  /* DMA2_Stream0_IRQn interrupt configuration */
  HAL_NVIC_SetPriority(DMA2_Stream0_IRQn, 2, 0);
  HAL_NVIC_EnableIRQ(DMA2_Stream0_IRQn);
  /* DMA2_Stream2_IRQn interrupt configuration */
  HAL_NVIC_SetPriority(DMA2_Stream2_IRQn, 2, 0);
  HAL_NVIC_EnableIRQ(DMA2_Stream2_IRQn);

}

/* FMC initialization function */
static void MX_FMC_Init(void)
{

  FMC_SDRAM_TimingTypeDef SdramTiming = {0};

  /** Perform the SDRAM1 memory initialization sequence
  */
  hsdram1.Instance = FMC_SDRAM_DEVICE;
  /* hsdram1.Init */
  hsdram1.Init.SDBank = FMC_SDRAM_BANK2;
  hsdram1.Init.ColumnBitsNumber = FMC_SDRAM_COLUMN_BITS_NUM_8;
  hsdram1.Init.RowBitsNumber = FMC_SDRAM_ROW_BITS_NUM_12;
  hsdram1.Init.MemoryDataWidth = FMC_SDRAM_MEM_BUS_WIDTH_16;
  hsdram1.Init.InternalBankNumber = FMC_SDRAM_INTERN_BANKS_NUM_4;
  hsdram1.Init.CASLatency = FMC_SDRAM_CAS_LATENCY_3;
  hsdram1.Init.WriteProtection = FMC_SDRAM_WRITE_PROTECTION_DISABLE;
  hsdram1.Init.SDClockPeriod = FMC_SDRAM_CLOCK_PERIOD_2;
  hsdram1.Init.ReadBurst = FMC_SDRAM_RBURST_DISABLE;
  hsdram1.Init.ReadPipeDelay = FMC_SDRAM_RPIPE_DELAY_1;
  /* SdramTiming */
  SdramTiming.LoadToActiveDelay = 2;
  SdramTiming.ExitSelfRefreshDelay = 7;
  SdramTiming.SelfRefreshTime = 4;
  SdramTiming.RowCycleDelay = 7;
  SdramTiming.WriteRecoveryTime = 3;
  SdramTiming.RPDelay = 2;
  SdramTiming.RCDDelay = 2;

  if (HAL_SDRAM_Init(&hsdram1, &SdramTiming) != HAL_OK)
  {
    Error_Handler( );
  }

}

static void MX_GPIO_Init(void)
{
  GPIO_InitTypeDef GPIO_InitStruct = {0};

  /* GPIO Ports Clock Enable */
  __HAL_RCC_GPIOE_CLK_ENABLE();
  __HAL_RCC_GPIOC_CLK_ENABLE();
  __HAL_RCC_GPIOF_CLK_ENABLE();
  __HAL_RCC_GPIOH_CLK_ENABLE();
  __HAL_RCC_GPIOA_CLK_ENABLE();
  __HAL_RCC_GPIOB_CLK_ENABLE();
  __HAL_RCC_GPIOG_CLK_ENABLE();
  __HAL_RCC_GPIOD_CLK_ENABLE();

  /*Configure GPIO pin Output Level */
  HAL_GPIO_WritePin(GPIOE, GPIO_PIN_2|GPIO_PIN_3, GPIO_PIN_RESET);

  /*Configure GPIO pin Output Level */
  HAL_GPIO_WritePin(GPIOC, NCS_MEMS_SPI_Pin|CSX_Pin|OTG_FS_PSO_Pin|GPIO_PIN_11, GPIO_PIN_RESET);

  /*Configure GPIO pin Output Level */
  HAL_GPIO_WritePin(GPIOD, RDX_Pin|WRX_DCX_Pin, GPIO_PIN_RESET);

  /*Configure GPIO pin Output Level */
  HAL_GPIO_WritePin(GPIOG, GPIO_PIN_2|LD3_Pin|LD4_Pin, GPIO_PIN_RESET);

  /*Configure GPIO pins : PE2 PE3 */
  GPIO_InitStruct.Pin = GPIO_PIN_2|GPIO_PIN_3;
  GPIO_InitStruct.Mode = GPIO_MODE_OUTPUT_PP;
  GPIO_InitStruct.Pull = GPIO_NOPULL;
  GPIO_InitStruct.Speed = GPIO_SPEED_FREQ_LOW;
  HAL_GPIO_Init(GPIOE, &GPIO_InitStruct);

  /*Configure GPIO pin : ENABLE_Pin */
  GPIO_InitStruct.Pin = ENABLE_Pin;
  GPIO_InitStruct.Mode = GPIO_MODE_AF_PP;
  GPIO_InitStruct.Pull = GPIO_NOPULL;
  GPIO_InitStruct.Speed = GPIO_SPEED_FREQ_LOW;
  GPIO_InitStruct.Alternate = GPIO_AF14_LTDC;
  HAL_GPIO_Init(ENABLE_GPIO_Port, &GPIO_InitStruct);

  /*Configure GPIO pins : NCS_MEMS_SPI_Pin CSX_Pin OTG_FS_PSO_Pin PC11 */
  GPIO_InitStruct.Pin = NCS_MEMS_SPI_Pin|CSX_Pin|OTG_FS_PSO_Pin|GPIO_PIN_11;
  GPIO_InitStruct.Mode = GPIO_MODE_OUTPUT_PP;
  GPIO_InitStruct.Pull = GPIO_NOPULL;
  GPIO_InitStruct.Speed = GPIO_SPEED_FREQ_LOW;
  HAL_GPIO_Init(GPIOC, &GPIO_InitStruct);

  /*Configure GPIO pin : PA0 */
  GPIO_InitStruct.Pin = GPIO_PIN_0;
  GPIO_InitStruct.Mode = GPIO_MODE_IT_RISING;
  GPIO_InitStruct.Pull = GPIO_NOPULL;
  HAL_GPIO_Init(GPIOA, &GPIO_InitStruct);

  /*Configure GPIO pins : MEMS_INT1_Pin MEMS_INT2_Pin TP_INT1_Pin */
  GPIO_InitStruct.Pin = MEMS_INT1_Pin|MEMS_INT2_Pin|TP_INT1_Pin;
  GPIO_InitStruct.Mode = GPIO_MODE_EVT_RISING;
  GPIO_InitStruct.Pull = GPIO_NOPULL;
  HAL_GPIO_Init(GPIOA, &GPIO_InitStruct);

  /*Configure GPIO pins : B5_Pin VSYNC_Pin G2_Pin R4_Pin
                           R5_Pin */
  GPIO_InitStruct.Pin = B5_Pin|VSYNC_Pin|G2_Pin|R4_Pin
                          |R5_Pin;
  GPIO_InitStruct.Mode = GPIO_MODE_AF_PP;
  GPIO_InitStruct.Pull = GPIO_NOPULL;
  GPIO_InitStruct.Speed = GPIO_SPEED_FREQ_LOW;
  GPIO_InitStruct.Alternate = GPIO_AF14_LTDC;
  HAL_GPIO_Init(GPIOA, &GPIO_InitStruct);

  /*Configure GPIO pins : R3_Pin R6_Pin */
  GPIO_InitStruct.Pin = R3_Pin|R6_Pin;
  GPIO_InitStruct.Mode = GPIO_MODE_AF_PP;
  GPIO_InitStruct.Pull = GPIO_NOPULL;
  GPIO_InitStruct.Speed = GPIO_SPEED_FREQ_LOW;
  GPIO_InitStruct.Alternate = GPIO_AF9_LTDC;
  HAL_GPIO_Init(GPIOB, &GPIO_InitStruct);

  /*Configure GPIO pin : BOOT1_Pin */
  GPIO_InitStruct.Pin = BOOT1_Pin;
  GPIO_InitStruct.Mode = GPIO_MODE_INPUT;
  GPIO_InitStruct.Pull = GPIO_NOPULL;
  HAL_GPIO_Init(BOOT1_GPIO_Port, &GPIO_InitStruct);

  /*Configure GPIO pins : G4_Pin G5_Pin B6_Pin B7_Pin */
  GPIO_InitStruct.Pin = G4_Pin|G5_Pin|B6_Pin|B7_Pin;
  GPIO_InitStruct.Mode = GPIO_MODE_AF_PP;
  GPIO_InitStruct.Pull = GPIO_NOPULL;
  GPIO_InitStruct.Speed = GPIO_SPEED_FREQ_LOW;
  GPIO_InitStruct.Alternate = GPIO_AF14_LTDC;
  HAL_GPIO_Init(GPIOB, &GPIO_InitStruct);

  /*Configure GPIO pins : OTG_HS_ID_Pin OTG_HS_DM_Pin OTG_HS_DP_Pin */
  GPIO_InitStruct.Pin = OTG_HS_ID_Pin|OTG_HS_DM_Pin|OTG_HS_DP_Pin;
  GPIO_InitStruct.Mode = GPIO_MODE_AF_PP;
  GPIO_InitStruct.Pull = GPIO_NOPULL;
  GPIO_InitStruct.Speed = GPIO_SPEED_FREQ_LOW;
  GPIO_InitStruct.Alternate = GPIO_AF12_OTG_HS_FS;
  HAL_GPIO_Init(GPIOB, &GPIO_InitStruct);

  /*Configure GPIO pin : VBUS_HS_Pin */
  GPIO_InitStruct.Pin = VBUS_HS_Pin;
  GPIO_InitStruct.Mode = GPIO_MODE_INPUT;
  GPIO_InitStruct.Pull = GPIO_NOPULL;
  HAL_GPIO_Init(VBUS_HS_GPIO_Port, &GPIO_InitStruct);

  /*Configure GPIO pin : TE_Pin */
  GPIO_InitStruct.Pin = TE_Pin;
  GPIO_InitStruct.Mode = GPIO_MODE_INPUT;
  GPIO_InitStruct.Pull = GPIO_NOPULL;
  HAL_GPIO_Init(TE_GPIO_Port, &GPIO_InitStruct);

  /*Configure GPIO pins : RDX_Pin WRX_DCX_Pin */
  GPIO_InitStruct.Pin = RDX_Pin|WRX_DCX_Pin;
  GPIO_InitStruct.Mode = GPIO_MODE_OUTPUT_PP;
  GPIO_InitStruct.Pull = GPIO_NOPULL;
  GPIO_InitStruct.Speed = GPIO_SPEED_FREQ_LOW;
  HAL_GPIO_Init(GPIOD, &GPIO_InitStruct);

  /*Configure GPIO pins : PG2 LD3_Pin LD4_Pin */
  GPIO_InitStruct.Pin = GPIO_PIN_2|LD3_Pin|LD4_Pin;
  GPIO_InitStruct.Mode = GPIO_MODE_OUTPUT_PP;
  GPIO_InitStruct.Pull = GPIO_NOPULL;
  GPIO_InitStruct.Speed = GPIO_SPEED_FREQ_LOW;
  HAL_GPIO_Init(GPIOG, &GPIO_InitStruct);

  /*Configure GPIO pins : PG3 PG9 */
  GPIO_InitStruct.Pin = GPIO_PIN_3|GPIO_PIN_9;
  GPIO_InitStruct.Mode = GPIO_MODE_INPUT;
  GPIO_InitStruct.Pull = GPIO_NOPULL;
  HAL_GPIO_Init(GPIOG, &GPIO_InitStruct);

  /*Configure GPIO pins : R7_Pin DOTCLK_Pin B3_Pin */
  GPIO_InitStruct.Pin = R7_Pin|DOTCLK_Pin|B3_Pin;
  GPIO_InitStruct.Mode = GPIO_MODE_AF_PP;
  GPIO_InitStruct.Pull = GPIO_NOPULL;
  GPIO_InitStruct.Speed = GPIO_SPEED_FREQ_LOW;
  GPIO_InitStruct.Alternate = GPIO_AF14_LTDC;
  HAL_GPIO_Init(GPIOG, &GPIO_InitStruct);

  /*Configure GPIO pins : HSYNC_Pin R2_Pin */
  GPIO_InitStruct.Pin = HSYNC_Pin|R2_Pin;
  GPIO_InitStruct.Mode = GPIO_MODE_AF_PP;
  GPIO_InitStruct.Pull = GPIO_NOPULL;
  GPIO_InitStruct.Speed = GPIO_SPEED_FREQ_LOW;
  GPIO_InitStruct.Alternate = GPIO_AF14_LTDC;
  HAL_GPIO_Init(GPIOC, &GPIO_InitStruct);

  /*Configure GPIO pin : I2C3_SDA_Pin */
  GPIO_InitStruct.Pin = I2C3_SDA_Pin;
  GPIO_InitStruct.Mode = GPIO_MODE_AF_OD;
  GPIO_InitStruct.Pull = GPIO_PULLUP;
  GPIO_InitStruct.Speed = GPIO_SPEED_FREQ_LOW;
  GPIO_InitStruct.Alternate = GPIO_AF4_I2C3;
  HAL_GPIO_Init(I2C3_SDA_GPIO_Port, &GPIO_InitStruct);

  /*Configure GPIO pin : I2C3_SCL_Pin */
  GPIO_InitStruct.Pin = I2C3_SCL_Pin;
  GPIO_InitStruct.Mode = GPIO_MODE_AF_OD;
  GPIO_InitStruct.Pull = GPIO_PULLUP;
  GPIO_InitStruct.Speed = GPIO_SPEED_FREQ_LOW;
  GPIO_InitStruct.Alternate = GPIO_AF4_I2C3;
  HAL_GPIO_Init(I2C3_SCL_GPIO_Port, &GPIO_InitStruct);

  /*Configure GPIO pins : G7_Pin B2_Pin */
  GPIO_InitStruct.Pin = G7_Pin|B2_Pin;
  GPIO_InitStruct.Mode = GPIO_MODE_AF_PP;
  GPIO_InitStruct.Pull = GPIO_NOPULL;
  GPIO_InitStruct.Speed = GPIO_SPEED_FREQ_LOW;
  GPIO_InitStruct.Alternate = GPIO_AF14_LTDC;
  HAL_GPIO_Init(GPIOD, &GPIO_InitStruct);

  /*Configure GPIO pins : PD4 PD5 */
  GPIO_InitStruct.Pin = GPIO_PIN_4|GPIO_PIN_5;
  GPIO_InitStruct.Mode = GPIO_MODE_IT_RISING;
  GPIO_InitStruct.Pull = GPIO_NOPULL;
  HAL_GPIO_Init(GPIOD, &GPIO_InitStruct);

  /*Configure GPIO pins : G3_Pin B4_Pin */
  GPIO_InitStruct.Pin = G3_Pin|B4_Pin;
  GPIO_InitStruct.Mode = GPIO_MODE_AF_PP;
  GPIO_InitStruct.Pull = GPIO_NOPULL;
  GPIO_InitStruct.Speed = GPIO_SPEED_FREQ_LOW;
  GPIO_InitStruct.Alternate = GPIO_AF9_LTDC;
  HAL_GPIO_Init(GPIOG, &GPIO_InitStruct);

}

/* USER CODE BEGIN 4 */
static void Sensors_Arm(void)
{
    __HAL_ADC_DISABLE(&hadc1);
    __HAL_ADC_DISABLE(&hadc2);

    /* Front sensor: DMA2_Stream0, channel 0, peripheral = &ADC1->DR */
    DMA2_Stream0->CR &= ~DMA_SxCR_EN;
    while (DMA2_Stream0->CR & DMA_SxCR_EN) { }
    DMA2->LIFCR = 0x3DU << 0;                  /* clear all flags for stream 0 */
    DMA2_Stream0->NDTR = 3000;
    DMA2_Stream0->PAR = (uint32_t)&ADC1->DR;
    DMA2_Stream0->M0AR = (uint32_t)FrontSensor_ORG;
    DMA2_Stream0->CR = (0U << 25)             /* CHSEL = channel 0 */
                       | DMA_SxCR_MINC          /* memory increment */
                       | DMA_SxCR_PSIZE_0       /* peripheral size = halfword */
                       | DMA_SxCR_MSIZE_0       /* memory size = halfword */
                       | DMA_SxCR_TCIE          /* TC interrupt */
                       | (2U << 16);            /* priority high */
    DMA2_Stream0->CR |= DMA_SxCR_EN;

    /* Rear sensor: DMA2_Stream2, channel 1, peripheral = &ADC2->DR */
    DMA2_Stream2->CR &= ~DMA_SxCR_EN;
    while (DMA2_Stream2->CR & DMA_SxCR_EN) { }
    DMA2->LIFCR = 0x3DU << 16;                 /* clear flags for stream 2 */
    DMA2_Stream2->NDTR = 3000;
    DMA2_Stream2->PAR = (uint32_t)&ADC2->DR;
    DMA2_Stream2->M0AR = (uint32_t)RearSensor_ORG;
    DMA2_Stream2->CR = (1U << 25)             /* CHSEL = channel 1 */
                       | DMA_SxCR_MINC
                       | DMA_SxCR_PSIZE_0
                       | DMA_SxCR_MSIZE_0
                       | DMA_SxCR_TCIE
                       | (2U << 16);
    DMA2_Stream2->CR |= DMA_SxCR_EN;

    ADC1->CR2 |= ADC_CR2_DMA | ADC_CR2_DDS;
    ADC2->CR2 |= ADC_CR2_DMA | ADC_CR2_DDS;
    ADC1->CR2 |= ADC_CR2_ADON;
    ADC2->CR2 |= ADC_CR2_ADON;

    edge_idx_after_idx = 0;
    adc_capture_done = 0;
    adc_swstart_count = 0;
    adc_armed = 1;
}

uint16_t findMin(uint16_t *buf)
{
    uint16_t min = buf[0];
    for (uint32_t i = 1; i < 3000; i++) {
        if (buf[i] < min) min = buf[i];
    }
    return min;
}

uint16_t findMax(uint16_t *buf)
{
    uint16_t max = buf[0];
    for (uint32_t i = 1; i < 3000; i++) {
        if (buf[i] > max) max = buf[i];
    }
    return max;
}

void EXTI_Init(void)
{
    /* 1. SYSCFG clock must be on to write EXTICR */
    __HAL_RCC_SYSCFG_CLK_ENABLE();

    /* 2a. Map EXTI0 to port A (source value 0x0) — SYSCFG_EXTICR1 bits[3:0] */
    SYSCFG->EXTICR[0] = (SYSCFG->EXTICR[0] & ~(0xF << 0)) | (0x0 << 0);

    /* 2b. Map EXTI4, EXTI5 to port D (source value 0x3) — SYSCFG_EXTICR2 */
    SYSCFG->EXTICR[1] = (SYSCFG->EXTICR[1]
                         & ~((0xF << 0) |  /* clear EXTI4 field */
                             (0xF << 4)))  /* clear EXTI5 field */
                        | (0x3 << 0)
                        | (0x3 << 4);

    /* 3. Unmask interrupt lines 0, 4, 5 */
    EXTI->IMR |= (1 << 0) | (1 << 4) | (1 << 5);

    /* 4. Rising-edge trigger on all three lines */
    EXTI->RTSR |= (1 << 0) | (1 << 4) | (1 << 5);

    /* 5. Falling-edge trigger on INA and INB only (IDX is rising-only) */
    EXTI->FTSR |= (1 << 4) | (1 << 5);

    /* 6. Clear any stale pending flags before opening the NVIC gate */
    EXTI->PR = (1 << 0) | (1 << 4) | (1 << 5);

    /* 7. NVIC — priority 0 (highest) for the hard-real-time encoder path.*/
    HAL_NVIC_SetPriority(EXTI0_IRQn, 0, 0);
    HAL_NVIC_EnableIRQ(EXTI0_IRQn);

    HAL_NVIC_SetPriority(EXTI4_IRQn, 0, 0);
    HAL_NVIC_EnableIRQ(EXTI4_IRQn);

    HAL_NVIC_SetPriority(EXTI9_5_IRQn, 0, 0);
    HAL_NVIC_EnableIRQ(EXTI9_5_IRQn);
}

static float rawToMm(uint16_t raw)
{
    float voltage = (float)raw * (3.0f / 4095.0f);
    float mm = (voltage - 0.125f) * (2.0f / 2.25f);
    if (mm < 0.0f) mm = 0.0f;
    if (mm > 2.0f) mm = 2.0f;
    return mm;
}

static void buildProcessedTable(uint16_t *src, float *dst)
{
    dst[0] = (rawToMm(src[0]) + rawToMm(src[1]) + rawToMm(src[2])) / 3.0f;

    for (uint32_t i = 1; i <= 298; i++) {
        uint32_t c = i * 10;
        dst[i] = (rawToMm(src[c - 2]) + rawToMm(src[c - 1]) + rawToMm(src[c]) + rawToMm(src[c + 1]) + rawToMm(src[c + 2])) / 5.0f;
    }

    dst[299] = (rawToMm(src[2997]) + rawToMm(src[2998]) + rawToMm(src[2999])) / 3.0f;
}

static void computeStats(uint16_t *buf, volatile float *out_min, volatile float *out_max, volatile float *out_avg)
{
    float mn = rawToMm(buf[0]);
    float mx = mn;
    float sum = mn;

    for (uint32_t i = 1; i < 3000; i++) {
        float d = rawToMm(buf[i]);
        if (d < mn) mn = d;
        if (d > mx) mx = d;
        sum += d;
    }

    *out_min = mn;
    *out_max = mx;
    *out_avg = sum / 3000.0f;
}

/* USER CODE END 4 */

void Error_Handler(void)
{
  __disable_irq();
  while (1)
  {
  }
}
